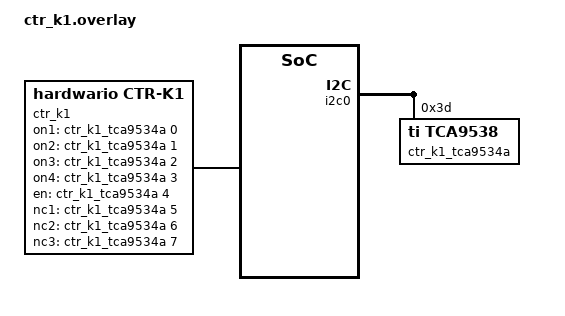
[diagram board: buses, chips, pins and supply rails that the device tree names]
/*
 * Copyright (c) 2023 HARDWARIO a.s.
 *
 * SPDX-License-Identifier: LicenseRef-HARDWARIO-5-Clause
 */

/ {
	ctr_k1: ctr_k1 {
		compatible = "hardwario,ctr-k1";
		status = "okay";
		on1-gpios = <&ctr_k1_tca9534a 0 GPIO_ACTIVE_HIGH>;
		on2-gpios = <&ctr_k1_tca9534a 1 GPIO_ACTIVE_HIGH>;
		on3-gpios = <&ctr_k1_tca9534a 2 GPIO_ACTIVE_HIGH>;
		on4-gpios = <&ctr_k1_tca9534a 3 GPIO_ACTIVE_HIGH>;
		en-gpios = <&ctr_k1_tca9534a 4 GPIO_ACTIVE_HIGH>;
		nc1-gpios = <&ctr_k1_tca9534a 5 GPIO_ACTIVE_HIGH>;
		nc2-gpios = <&ctr_k1_tca9534a 6 GPIO_ACTIVE_HIGH>;
		nc3-gpios = <&ctr_k1_tca9534a 7 GPIO_ACTIVE_HIGH>;
	};
};

&i2c0 {
	ctr_k1_tca9534a: ctr_k1_tca9534a@3d {
		compatible = "ti,tca9538";
		status = "okay";
		reg = <0x3d>;
		#gpio-cells = <2>;
		gpio-controller;
		ngpios = <8>;
	};
};
